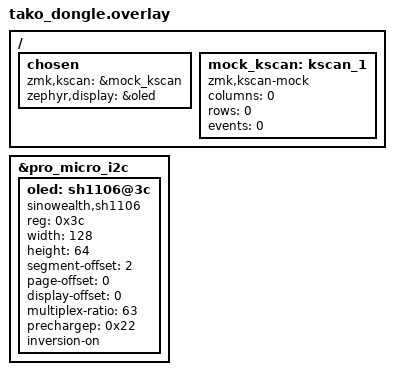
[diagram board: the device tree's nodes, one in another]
/* nice!nano + SH1106 OLED, matching zmk-config-totem feature/dongle_miryoku. */
#include "tako-layouts.dtsi"

/ {
    chosen {
        zmk,kscan = &mock_kscan;
        zephyr,display = &oled;
    };

    mock_kscan: kscan_1 {
        compatible = "zmk,kscan-mock";
        columns = <0>;
        rows = <0>;
        events = <0>;
    };
};

&pro_micro_i2c {
    status = "okay";

    oled: sh1106@3c {
        compatible = "sinowealth,sh1106";
        reg = <0x3c>;
        width = <128>;
        height = <64>;
        segment-offset = <2>;
        page-offset = <0>;
        display-offset = <0>;
        multiplex-ratio = <63>;
        /* Reverse both scan axes: 180 degrees relative to the original
         * segment-remap + com-invdir mounting. Keep colour inversion below. */
        /delete-property/ segment-remap;
        /delete-property/ com-invdir;
        prechargep = <0x22>;
        /* Invert colours for the entire framebuffer, including bitmap widgets. */
        inversion-on;
    };
};
